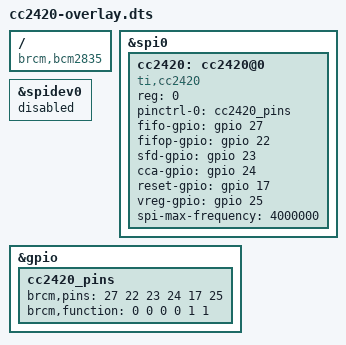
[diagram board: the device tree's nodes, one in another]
/dts-v1/;
/plugin/;

/* Overlay for TI CC2420 IEEE 802.15.4 WPAN transceiver on spi0.0 */

/ {
	compatible = "brcm,bcm2835", "brcm,bcm2836", "brcm,bcm2708", "brcm,bcm2709";

	fragment@0 {
		target = <&spi0>;
		__overlay__ {
			#address-cells = <1>;
			#size-cells = <0>;

			status = "okay";

			cc2420: cc2420@0 {
				compatible = "ti,cc2420";
				reg = <0>;
				pinctrl-names = "default";
				pinctrl-0 = <&cc2420_pins>;
				fifo-gpio = <&gpio 27 0>;
				fifop-gpio = <&gpio 22 0>;
				sfd-gpio = <&gpio 23 0>;
				cca-gpio = <&gpio 24 0>;
				reset-gpio = <&gpio 17 0>;
				vreg-gpio = <&gpio 25 0>;
				spi-max-frequency = <4000000>;
			};
		};
	};

	fragment@1 {
		target = <&spidev0>;
		__overlay__ {
			status = "disabled";
		};
	};

	fragment@2 {
		target = <&gpio>;
		__overlay__ {
			cc2420_pins: cc2420_pins {
				brcm,pins = <27 22 23 24 17 25>;
				brcm,function = <0 0 0 0 1 1>; /* in in in in out out */
			};
		};
	};


	__overrides__ {
		reset     = <&cc2420>, "reset-gpio:4",
			<&cc2420_pins>, "brcm,pins:4";
		fifo     = <&cc2420>, "sleep-gpio:4",
			<&cc2420_pins>, "brcm,pins:8";
		fifop     = <&cc2420>, "sleep-gpio:4",
			<&cc2420_pins>, "brcm,pins:8";
		sfd     = <&cc2420>, "sleep-gpio:4",
			<&cc2420_pins>, "brcm,pins:8";
		cca     = <&cc2420>, "sleep-gpio:4",
			<&cc2420_pins>, "brcm,pins:8";
		vreg     = <&cc2420>, "sleep-gpio:4",
			<&cc2420_pins>, "brcm,pins:8";
		speed     = <&cc2420>, "spi-max-frequency:0";
	};
};
